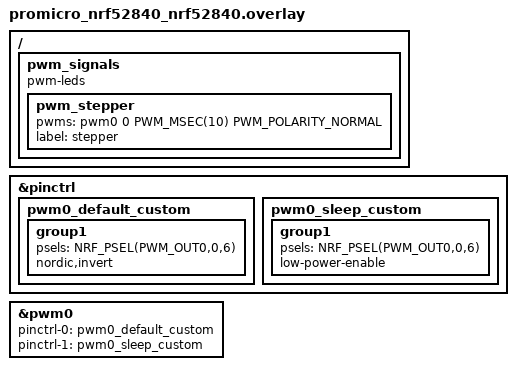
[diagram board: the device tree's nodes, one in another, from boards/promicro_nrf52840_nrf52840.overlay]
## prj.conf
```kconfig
CONFIG_GPIO=y

CONFIG_BUILD_OUTPUT_UF2=y
CONFIG_FLASH_LOAD_OFFSET=0x1000

CONFIG_PWM=y

CONFIG_LED=y
CONFIG_LED_PWM=y



CONFIG_STDOUT_CONSOLE=y
CONFIG_PRINTK=y
CONFIG_LOG=y
CONFIG_LOG_PRINTK=y
CONFIG_LOG_MODE_IMMEDIATE=y
CONFIG_PWM_LOG_LEVEL_DBG=y
```

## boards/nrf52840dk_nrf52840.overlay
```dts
&pinctrl {
  pwm0_default_custom: pwm0_default_custom {
    group1 {
      psels = <NRF_PSEL(PWM_OUT0,0,13)>;
      nordic,invert;
    };
  };
  pwm0_sleep_custom: pwm0_sleep_custom {
    group1 {
      psels = <NRF_PSEL(PWM_OUT0,0,13)>;
      low-power-enable;
    };
  };

};

&pwm0 {
  status = "okay";
  // set pin control 0 to output mode
  pinctrl-0 = <&pwm0_default_custom>;
  pinctrl-1 = <&pwm0_sleep_custom>;
  // change pin control to only be out and no low power mode
  pinctrl-names = "default","sleep";
};

/ {
  servo: servo{
    compatible = "pwm-servo";
    status = "okay";
    pwms = <&pwm0 0 PWM_MSEC(20) PWM_POLARITY_NORMAL>;
    min-pulse = <PWM_USEC(700)>;
    max-pulse = <PWM_USEC(2500)>;
  };
};
```

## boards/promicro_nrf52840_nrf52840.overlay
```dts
&pinctrl {
  pwm0_default_custom: pwm0_default_custom {
    group1 {
      psels = <NRF_PSEL(PWM_OUT0,0,6)>;
      nordic,invert;
    };
  };
  pwm0_sleep_custom: pwm0_sleep_custom {
    group1 {
      psels = <NRF_PSEL(PWM_OUT0,0,6)>;
      low-power-enable;
    };
  };
};

&pwm0 {
  status = "okay";
  // set pin control 0 to output mode
  pinctrl-0 = <&pwm0_default_custom>;
  pinctrl-1 = <&pwm0_sleep_custom>;
  // change pin control to only be out and no low power mode
  pinctrl-names = "default","sleep";
};

/ {
  pwm_signals: pwm_signals{
    compatible = "pwm-leds";
    pwm_stepper: pwm_stepper {
        pwms = <&pwm0 0 PWM_MSEC(10) PWM_POLARITY_NORMAL>;
        label = "stepper";
    };
  };
};
```

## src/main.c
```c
#include <zephyr/drivers/pwm.h>
#include <zephyr/kernel.h>
#include <zephyr/sys/printk.h>

#define PWM_PERIOD_NS 20000000
#define PWM_PULSE_WIDTH 1400000

static const struct pwm_dt_spec pwm_led0 = PWM_DT_SPEC_GET(DT_NODELABEL(pwm_stepper));

int main(void) {
  if (!pwm_is_ready_dt(&pwm_led0)) {
    printk("Error: PWM device %s is not ready\n", pwm_led0.dev->name);
    return 0;
  }
  int err = pwm_set_dt(&pwm_led0,PWM_PERIOD_NS, PWM_PULSE_WIDTH);
  if (err){
    printk("Error in pmw_set_dt(), err %d",err);
    return 0;
  }

  return 0;
}
```
